# CH32V407 register map
Vendor: WCH Ltd.; File version: 1.0
Registers are 32-bit, read-write, reset 0x0 unless marked. A register's access mark holds for its fields unless they carry their own. Offsets are from the block's base; [hi:lo] are bit positions.

## TIM6 — Basic timer
Base 0x40001000
Same registers: TIM7 0x40001400
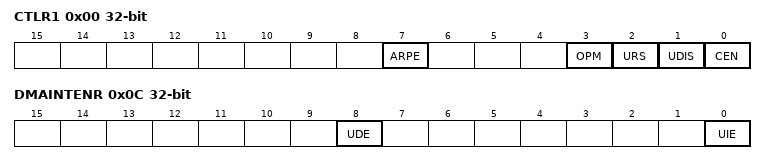
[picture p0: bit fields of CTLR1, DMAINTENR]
0x00 CTLR1 — control register 1
  [7] ARPE — Auto-reload preload enable
  [3] OPM — One-pulse mode
  [2] URS — Update request source
  [1] UDIS — Update disable
  [0] CEN — Counter enable
0x04 CTLR2 — control register 2
  [6:4] MMS — Master mode selection
0x0C DMAINTENR — DMA/Interrupt enable register
  [8] UDE — Update DMA request enable
  [0] UIE — Update interrupt enable
0x10 INTFR — status register
  [0] UIF — Update interrupt flag
0x14 SWEVGR wo — event generation register
  [0] UG — Update generation
0x24 CNT — counter
  [15:0] CNT — counter value
0x28 PSC — prescaler
  [15:0] PSC — Prescaler value
0x2C ATRLR reset 0xFFFF — auto-reload register
  [15:0] ARR — Auto-reload value

## USART1 — Universal synchronous asynchronous receiver transmitter
Base 0x40013800
Same registers: USART6 0x40001800, USART7 0x40001C00, USART8 0x40002000, USART2 0x40004400, USART3 0x40004800, USART4 0x40004C00, USART5 0x40005000, USART9 0x40007800, USART10 0x40007C00
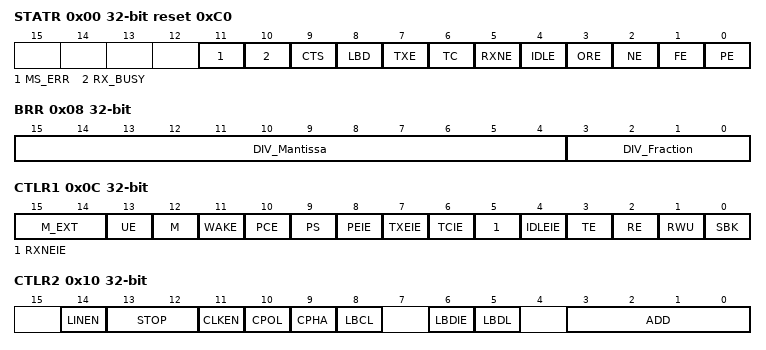
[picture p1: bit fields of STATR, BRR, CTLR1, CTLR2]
0x00 STATR access per field reset 0xC0 — Status register
  [11] MS_ERR ro — MARK or SPACE check error flag
  [10] RX_BUSY ro — receive status indication bit
  [9] CTS rw — CTS flag
  [8] LBD rw — LIN break detection flag
  [7] TXE ro — Transmit data register empty
  [6] TC rw — Transmission complete
  [5] RXNE rw — Read data register not empty
  [4] IDLE ro — IDLE line detected
  [3] ORE ro — Overrun error
  [2] NE ro — Noise error flag
  [1] FE ro — Framing error
  [0] PE ro — Parity error
0x04 DATAR — Data register
  [8:0] DR — Data value
0x08 BRR — Baud rate register
  [15:4] DIV_Mantissa — mantissa of USARTDIV
  [3:0] DIV_Fraction — fraction of USARTDIV
0x0C CTLR1 — Control register 1
  [15:14] M_EXT — data length extension bit
  [13] UE — USART enable
  [12] M — Word length
  [11] WAKE — Wakeup method
  [10] PCE — Parity control enable
  [9] PS — Parity selection
  [8] PEIE — PE interrupt enable
  [7] TXEIE — TXE interrupt enable
  [6] TCIE — Transmission complete interrupt enable
  [5] RXNEIE — RXNE interrupt enable
  [4] IDLEIE — IDLE interrupt enable
  [3] TE — Transmitter enable
  [2] RE — Receiver enable
  [1] RWU — Receiver wakeup
  [0] SBK — Send break
0x10 CTLR2 — Control register 2
  [14] LINEN — LIN mode enable
  [13:12] STOP — STOP bits
  [11] CLKEN — Clock enable
  [10] CPOL — Clock polarity
  [9] CPHA — Clock phase
  [8] LBCL — Last bit clock pulse
  [6] LBDIE — LIN break detection interrupt enable
  [5] LBDL — lin break detection length
  [3:0] ADD — Address of the USART node
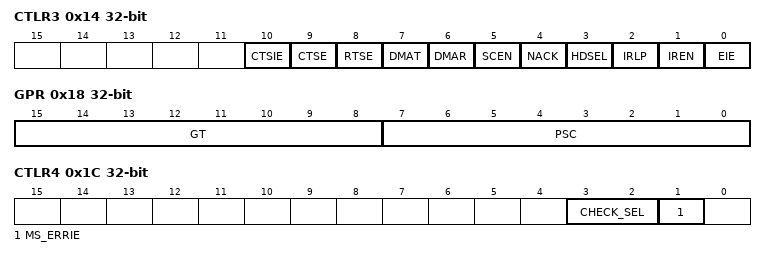
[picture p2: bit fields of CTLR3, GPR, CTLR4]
0x14 CTLR3 — Control register 3
  [10] CTSIE — CTS interrupt enable
  [9] CTSE — CTS enable
  [8] RTSE — RTS enable
  [7] DMAT — DMA enable transmitter
  [6] DMAR — DMA enable receiver
  [5] SCEN — Smartcard mode enable
  [4] NACK — Smartcard NACK enable
  [3] HDSEL — Half-duplex selection
  [2] IRLP — IrDA low-power
  [1] IREN — IrDA mode enable
  [0] EIE — Error interrupt enable
0x18 GPR — Guard time and prescaler register
  [15:8] GT — Guard time value
  [7:0] PSC — Prescaler value
0x1C CTLR4 — Control register 4
  [3:2] CHECK_SEL — check function selection bit
  [1] MS_ERRIE — SPACE or mark check error enable bit

## I2C — Inter integrated circuit
Base 0x40005400
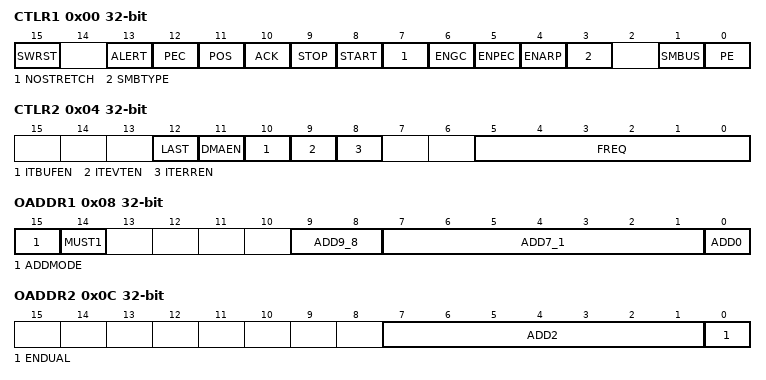
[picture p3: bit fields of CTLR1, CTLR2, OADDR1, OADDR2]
0x00 CTLR1 — Control register 1
  [15] SWRST — Software reset
  [13] ALERT — SMBus alert
  [12] PEC — Packet error checking
  [11] POS — Acknowledge/PEC Position (for data reception)
  [10] ACK — Acknowledge enable
  [9] STOP — Stop generation
  [8] START — Start generation
  [7] NOSTRETCH — Clock stretching disable (Slave mode)
  [6] ENGC — General call enable
  [5] ENPEC — PEC enable
  [4] ENARP — ARP enable
  [3] SMBTYPE — SMBus type
  [1] SMBUS — SMBus mode
  [0] PE — Peripheral enable
0x04 CTLR2 — Control register 2
  [12] LAST — DMA last transfer
  [11] DMAEN — DMA requests enable
  [10] ITBUFEN — Buffer interrupt enable
  [9] ITEVTEN — Event interrupt enable
  [8] ITERREN — Error interrupt enable
  [5:0] FREQ — Peripheral clock frequency
0x08 OADDR1 — Own address register 1
  [15] ADDMODE — Addressing mode (slave mode)
  [14] MUST1 — Must be 1
  [9:8] ADD9_8 — Interface address
  [7:1] ADD7_1 — Interface address
  [0] ADD0 — Interface address
0x0C OADDR2 — Own address register 2
  [7:1] ADD2 — Interface address
  [0] ENDUAL — Dual addressing mode enable
0x10 DATAR — Data register
  [7:0] DATAR — 8-bit data register
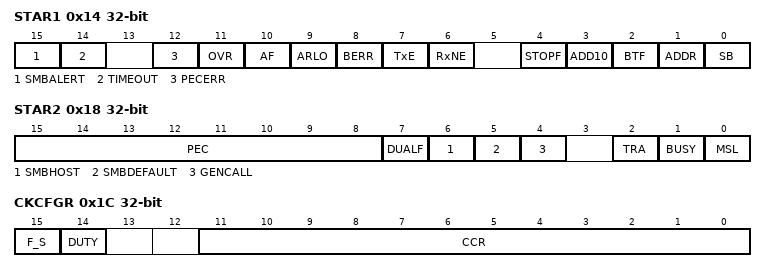
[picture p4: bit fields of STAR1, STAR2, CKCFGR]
0x14 STAR1 access per field — Status register 1
  [15] SMBALERT rw — SMBus alert
  [14] TIMEOUT rw — Timeout or Tlow error
  [12] PECERR rw — PEC Error in reception
  [11] OVR rw — Overrun/Underrun
  [10] AF rw — Acknowledge failure
  [9] ARLO rw — Arbitration lost (master mode)
  [8] BERR rw — Bus error
  [7] TxE ro — Data register empty (transmitters)
  [6] RxNE ro — Data register not empty (receivers)
  [4] STOPF ro — Stop detection (slave mode)
  [3] ADD10 ro — 10-bit header sent (Master mode)
  [2] BTF ro — Byte transfer finished
  [1] ADDR ro — Address sent (master mode)/matched (slave mode)
  [0] SB ro — Start bit (Master mode)
0x18 STAR2 ro — Status register 2
  [15:8] PEC — acket error checking register
  [7] DUALF — Dual flag (Slave mode)
  [6] SMBHOST — SMBus host header (Slave mode)
  [5] SMBDEFAULT — SMBus device default address (Slave mode)
  [4] GENCALL — General call address (Slave mode)
  [2] TRA — Transmitter/receiver
  [1] BUSY — Bus busy
  [0] MSL — Master/slave
0x1C CKCFGR — Clock control register
  [15] F_S — I2C master mode selection
  [14] DUTY — Fast mode duty cycle
  [11:0] CCR — Clock control register in Fast/Standard mode (Master mode)
0x20 RTR reset 0x2 — Raise time register
  [5:0] TRISE — Maximum rise time in Fast/Standard mode (Master mode)
